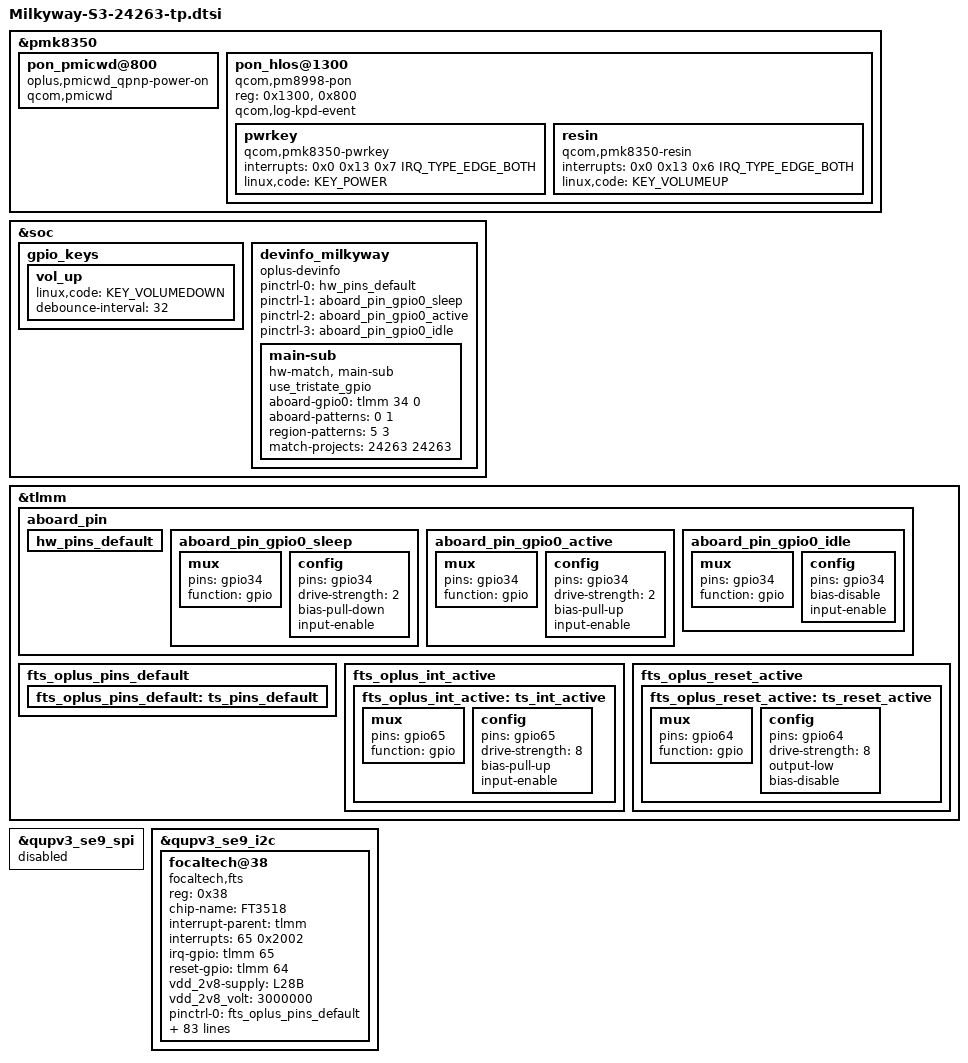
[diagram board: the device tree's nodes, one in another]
&pmk8350 {
	/delete-node/ pon_hlos@1300;

	pon_pmicwd@800 {
		compatible = "oplus,pmicwd_qpnp-power-on";
		qcom,pmicwd;
	};

	pon_hlos@1300 {
		compatible = "qcom,pm8998-pon";
		reg = <0x1300>, <0x800>;
		reg-names = "pon_hlos", "pon_pbs";
		qcom,log-kpd-event;

		pwrkey {
			compatible = "qcom,pmk8350-pwrkey";
			interrupts = <0x0 0x13 0x7 IRQ_TYPE_EDGE_BOTH>;
			linux,code = <KEY_POWER>;
		};

		resin {
			compatible = "qcom,pmk8350-resin";
			interrupts = <0x0 0x13 0x6 IRQ_TYPE_EDGE_BOTH>;
			linux,code = <KEY_VOLUMEUP>;
		};
	};
};

&soc {
	gpio_keys {
		vol_up {
			linux,code = <KEY_VOLUMEDOWN>;
			debounce-interval = <32>;
		};
	};
};

&soc {
	devinfo_milkyway {
		compatible = "oplus-devinfo";
		pinctrl-names = "default", "sleep", "active", "idle";
		pinctrl-0 = <&hw_pins_default>;
		pinctrl-1 = <&aboard_pin_gpio0_sleep>;
		pinctrl-2 = <&aboard_pin_gpio0_active>;
		pinctrl-3 = <&aboard_pin_gpio0_idle>;

		main-sub {
			compatible = "hw-match, main-sub";
			use_tristate_gpio;
			aboard-gpio0 = <&tlmm 34 0>;
			aboard-patterns = <0 1>;	/*0[high-resistance] 1[pull-down] 2[pull-up]*/
			/*region id*/
			region-patterns = <5 3>;	/*3[EU] 5[Asia] 4[US]*/
			/*main board*/
			match-projects = <24263 24263>;
		};
	};
};

&tlmm {
	aboard_pin {
		hw_pins_default:hw_pins_default {
		};

		aboard_pin_gpio0_sleep:aboard_pin_gpio0_sleep {
			mux {
				pins = "gpio34";
				function = "gpio";
			};
			config {
				pins = "gpio34";
				drive-strength = <2>;
				bias-pull-down;
				input-enable;
			};
		};

		aboard_pin_gpio0_active:aboard_pin_gpio0_active {
			mux {
				pins = "gpio34";
				function = "gpio";
			};
			config {
				pins = "gpio34";
				drive-strength = <2>;
				bias-pull-up;
				input-enable;
			};
		};

		aboard_pin_gpio0_idle:aboard_pin_gpio0_idle {
			mux {
				pins = "gpio34";
				function = "gpio";
			};
			config {
				pins = "gpio34";
				bias-disable;
				input-enable;
			};
		};
	};
};

&qupv3_se9_spi{
	status = "disabled";
};

&qupv3_se9_i2c {
    status = "ok";
    #address-cells = <1>;
    #size-cells = <0>;

    focaltech@38 {
        compatible = "focaltech,fts";
        reg = <0x38>;
        chip-name = "FT3518";
        status = "ok";

        /* Interrupt && Irq-gpio */
        interrupt-parent = <&tlmm>;
        interrupts = <65 0x2002>;
        irq-gpio = <&tlmm 65 0x2002>;
        reset-gpio = <&tlmm 64 0x00>;

        /* Power Config */
        //enable2v8_gpio = <&tlmm 102 0x1>;
        //enable1v8_gpio = <&tlmm 97 0x1>;
        vdd_2v8-supply = <&L28B>;
        //vcc_1v8-supply = <&L9A>;
        vdd_2v8_volt = <3000000>;

        /* Other HW Resource */
        pinctrl-names = "default";
        pinctrl-0 = <&fts_oplus_pins_default>;

        touchpanel,max-num-support = <10>;
        touchpanel,tx-rx-num = <16 34>;
        touchpanel,panel-coords = <8640 19200>;
        touchpanel,display-coords = <1080 2400>;
        touchpanel,touchmajor-limit = <0 54>;
        touchpanel,smooth-level = <255 2 15 25 45 60>;
        touchpanel,smooth-level-charging = <255 15 20 25 45 60>;
        touchpanel,sensitive-level = <255 20 17 14 10 8>;
        touchpanel,high-frame-rate-time = <20>;
        touchpanel,single-optimized-time = <8>;

        panel_type = <8>;
        // type of tp_dev ,TP-SAMSUNG = 8;
        firmware_name = "0xAC570500";
        platform_support_project = <24263 24264>;
        platform_support_project_dir = <24263 24263>;
        platform_support_project_commandline = "default_commandline","default_commandline";

        prevention,curved_screen_V2;
        prevention,grip_disable_level = <6>;
        prevention,updelay_time_ms = <30>;
        prevention,makeup_cnt_weight = <4 1 2 2 2>;
        prevention,large_corner_range = <960 2400>;
        prevention,large_corner_judge_condition = <500 300 800 7 7>;
        prevention,trx_reject_condition = <9 6 7>;
        prevention,trx_strict_reject_condition = <8 5 6>;
        prevention,large_judge_time_ms = <500 50 30>;
        prevention,large_exit_condition = <8 8 2>;
        prevention,single_channel_width = <160 160>;
        prevention,normal_tap_condition = <10 350>;
        prevention,long_edge_condition = <200 80 180 80>;
        prevention,long_strict_edge_condition = <160 60>;
        prevention,long_fingerhold_condition = <50 6 4 4>;
        prevention,short_edge_condition = <200 80 180 80>;
        prevention,short_strict_edge_condition = <160 60>;
        prevention,large_strict_exit_condition = <4 4>;
        prevention,top_corner_config = <440 1200 360>;
        prevention,edge_swipe_config = <240 960>;

        prevention,curved_screen_V4;
        prevention,long_eliminate_point_type = <2 8640 6400 240 19200 300 1>;
        prevention,long_fingerhold_condition2 = <420 0 0 0>;
        prevention,top_corner_config2 = <3 80 480 0 0>;
        prevention,hor_long_top_corner_config = <240 1600 0 0>;
        prevention,top_middle_config = <8640 800 800 0>;
        prevention,corner_eliminate_point_type = <0 960 1600 1>;
        prevention,finger_hold_differ_size = <1 0 240 300>;
        prevention,finger_hold_max_rx_exit_distance = <5 240 1600>;
        prevention,max_rx_exit_distance = <1 5 150 240 1600>;
        prevention,dynamic_finger_hold_exit_distance = <1 240 1600 360>;
        prevention,edge_sliding_matched_support = <1 150 3 0>;

        //grip v4.2 reclining mode -> not support in Camry
        /*prevention,reclining_mode_support = <1>;
        prevention,long_eliminate_point_type_recli = <2 8640 6400 240 19200 500 0>;
        prevention,finger_hold_differ_size_recli = <1 0 240 400>;
        prevention,finger_hold_max_rx_exit_distance_recli = <4 240 1600>;
        prevention,max_rx_exit_distance_recli = <1 4 100 240 1600>;
        prevention,dynamic_finger_hold_exit_distance_recli = <1 240 1600 360>;
        prevention,edge_sliding_matched_support_recli = <1 200 3 0>;
        prevention,long_edge_condition_recli = <160 80 120 80>;*/

        /* SW Support Feature Control */
        black_gesture_support;
        black_gesture_indep_support;
        sportify_aod_gesture_support;
        pressure_report_support;
        charger_pump_support;
        game_switch_support;
        smart_gesture_support;
        fw_update_app_support;
        fingerprint_underscreen_support;
        screenoff_fingerprint_info_support;
        irq_need_dev_resume_ok;
        kernel_grip_support;
        //fw_edge_limit_support;
        exception_upload_support;
        health_monitor_support;
        //focalt x8 resolution config
        high_resolution_support;
        high_resolution_support_x8;
        disable_suspend_irq_handler_support;
        palm_to_sleep_support;
        snr_read_support;
        fingerprint_not_report_in_suspend;
	glove_mode_v2_support;
	disable_touch_event_support;
        /*
            *Virtual Key Config:
            *1:touchpanel,button-type: <virtualkey_type  supportted_button-map>
            *virtualkey_type:
            *Type 1: using board_properties
            *Type 2: using same IC (button zone&& touch zone are seprate)
            *Type 3: using diffrent IC (button zone&& touch zone are seprate)
            *Type 4: No need of virtual key process
            *supportted_button-map:select|menu|home|back
            *
            *2:touchpanel,button-map
            *type (X1,Y1)(X2,Y2)(X3,Y3)(Width_X,Hight_Y)--Only when button-type is 0
        */
        touchpanel,button-type = <4>;
        touchpanel.button-TRx = <0 0>;
    };
};

&tlmm {
	fts_oplus_pins_default {
		fts_oplus_pins_default: ts_pins_default {
		};
	};

	fts_oplus_int_active {
		fts_oplus_int_active: ts_int_active {
			mux {
				pins = "gpio65";
				function = "gpio";
			};

			config {
				pins = "gpio65";
				drive-strength = <8>;
				bias-pull-up;
				input-enable;
			};
		};
	};

	fts_oplus_reset_active {
		fts_oplus_reset_active: ts_reset_active {
			mux {
				pins = "gpio64";
				function = "gpio";
			};

			config {
				pins = "gpio64";
				drive-strength = <8>;
				output-low;
				bias-disable;
			};
		};
	};
//#endif /*OPLUS_FEATURE_TP_BASIC*/
};
